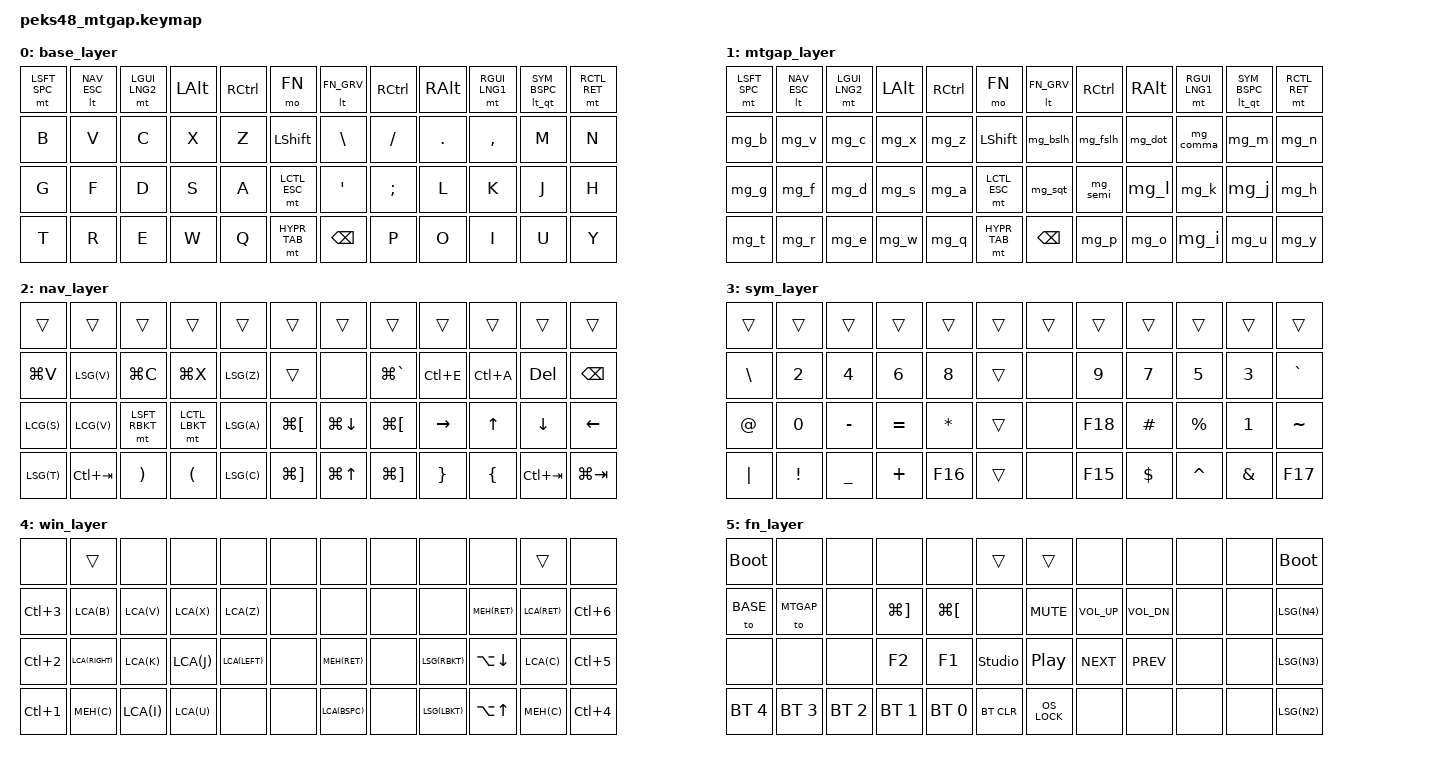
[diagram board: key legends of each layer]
// Includes {{{

#include <input/processors.dtsi>
#include <dt-bindings/zmk/input_transform.h>
#include <zephyr/dt-bindings/input/input-event-codes.h>
#include <behaviors.dtsi>
#include <dt-bindings/zmk/bt.h>
#include <dt-bindings/zmk/keys.h>
#include <dt-bindings/zmk/pointing.h>
#include <dt-bindings/zmk/behaviors.h>

// }}}

// Macros {{{

// Layers
#define BASE  0
#define MTGAP 1
#define NAV   2
#define SYM   3
#define WIN   4
#define FN    5

// Modifiers
#define LSG(key) LS(LG(key))
#define LCA(key) LC(LA(key))
#define LCG(key) LC(LG(key))
#define MEH(key) LS(LC(LA(key)))
#define HYPER    RC(RA(RG(RSHIFT)))

// Layer-Tap
#define NAV_ESC  NAV ESC
#define SYM_BSPC SYM BSPC
#define FN_GRV   FN  GRAVE

// Mod-Tap
#define HYPR_TAB  HYPER  TAB
#define LSFT_SPC  LSHIFT SPACE
#define RCTL_RET  RCTRL  RET
#define LCTL_ESC  LCTRL  ESC
#define LGUI_LNG2 LGUI   LANG2
#define RGUI_LNG1 RGUI   LANG1
#define RGUI_TAB  RGUI   TAB
#define LCTL_LBKT LCTRL  LBKT
#define LSFT_RBKT LSHIFT RBKT

// Otherwise
#define OS_LOCK LCG(Q)

// }}}

// Behavior Configuration {{{

&mt {
    tapping-term-ms = <150>;
};

&lt {
    flavor = "hold-preferred";
    tapping-term-ms = <150>;
};

// }}}

/ {

    // Behaviors {{{

    behaviors {

        mt_qt: mod_tap_with_quick_tap {
            compatible = "zmk,behavior-hold-tap";
            #binding-cells = <2>;
            flavor = "hold-preferred";
            tapping-term-ms = <150>;
            quick-tap-ms = <150>;
            bindings = <&kp>, <&kp>;
            display-name = "Mod-Tap";
        };

        lt_qt: layer_tap_with_quick_tap {
            compatible = "zmk,behavior-hold-tap";
            #binding-cells = <2>;
            flavor = "hold-preferred";
            tapping-term-ms = <150>;
            quick-tap-ms = <150>;
            bindings = <&mo>, <&kp>;
            display-name = "Layer-Tap";
        };

        // MTGAP {{{

        mg_a: mtgap_a {
            compatible = "zmk,behavior-mod-morph";
            #binding-cells = <0>;
            bindings = <&kp I>, <&kp A>;
            mods = <(MOD_LCTL|MOD_RCTL|MOD_LGUI|MOD_RGUI)>;
            keep-mods = <(MOD_LCTL|MOD_RCTL|MOD_LGUI|MOD_RGUI)>;
        };

        mg_b: mtgap_b {
            compatible = "zmk,behavior-mod-morph";
            #binding-cells = <0>;
            bindings = <&kp SEMI>, <&kp B>;
            mods = <(MOD_LCTL|MOD_RCTL|MOD_LGUI|MOD_RGUI)>;
            keep-mods = <(MOD_LCTL|MOD_RCTL|MOD_LGUI|MOD_RGUI)>;
        };

        mg_c: mtgap_c {
            compatible = "zmk,behavior-mod-morph";
            #binding-cells = <0>;
            bindings = <&kp SQT>, <&kp C>;
            mods = <(MOD_LCTL|MOD_RCTL|MOD_LGUI|MOD_RGUI)>;
            keep-mods = <(MOD_LCTL|MOD_RCTL|MOD_LGUI|MOD_RGUI)>;
        };

        mg_d: mtgap_d {
            compatible = "zmk,behavior-mod-morph";
            #binding-cells = <0>;
            bindings = <&kp E>, <&kp D>;
            mods = <(MOD_LCTL|MOD_RCTL|MOD_LGUI|MOD_RGUI)>;
            keep-mods = <(MOD_LCTL|MOD_RCTL|MOD_LGUI|MOD_RGUI)>;
        };

        mg_e: mtgap_e {
            compatible = "zmk,behavior-mod-morph";
            #binding-cells = <0>;
            bindings = <&kp O>, <&kp E>;
            mods = <(MOD_LCTL|MOD_RCTL|MOD_LGUI|MOD_RGUI)>;
            keep-mods = <(MOD_LCTL|MOD_RCTL|MOD_LGUI|MOD_RGUI)>;
        };

        mg_f: mtgap_f {
            compatible = "zmk,behavior-mod-morph";
            #binding-cells = <0>;
            bindings = <&kp A>, <&kp F>;
            mods = <(MOD_LCTL|MOD_RCTL|MOD_LGUI|MOD_RGUI)>;
            keep-mods = <(MOD_LCTL|MOD_RCTL|MOD_LGUI|MOD_RGUI)>;
        };

        mg_g: mtgap_g {
            compatible = "zmk,behavior-mod-morph";
            #binding-cells = <0>;
            bindings = <&kp COMMA>, <&kp G>;
            mods = <(MOD_LCTL|MOD_RCTL|MOD_LGUI|MOD_RGUI)>;
            keep-mods = <(MOD_LCTL|MOD_RCTL|MOD_LGUI|MOD_RGUI)>;
        };

        mg_h: mtgap_h {
            compatible = "zmk,behavior-mod-morph";
            #binding-cells = <0>;
            bindings = <&kp M>, <&kp H>;
            mods = <(MOD_LCTL|MOD_RCTL|MOD_LGUI|MOD_RGUI)>;
            keep-mods = <(MOD_LCTL|MOD_RCTL|MOD_LGUI|MOD_RGUI)>;
        };

        mg_i: mtgap_i {
            compatible = "zmk,behavior-mod-morph";
            #binding-cells = <0>;
            bindings = <&kp L>, <&kp I>;
            mods = <(MOD_LCTL|MOD_RCTL|MOD_LGUI|MOD_RGUI)>;
            keep-mods = <(MOD_LCTL|MOD_RCTL|MOD_LGUI|MOD_RGUI)>;
        };

        mg_j: mtgap_j {
            compatible = "zmk,behavior-mod-morph";
            #binding-cells = <0>;
            bindings = <&kp H>, <&kp J>;
            mods = <(MOD_LCTL|MOD_RCTL|MOD_LGUI|MOD_RGUI)>;
            keep-mods = <(MOD_LCTL|MOD_RCTL|MOD_LGUI|MOD_RGUI)>;
        };

        mg_k: mtgap_k {
            compatible = "zmk,behavior-mod-morph";
            #binding-cells = <0>;
            bindings = <&kp T>, <&kp K>;
            mods = <(MOD_LCTL|MOD_RCTL|MOD_LGUI|MOD_RGUI)>;
            keep-mods = <(MOD_LCTL|MOD_RCTL|MOD_LGUI|MOD_RGUI)>;
        };

        mg_l: mtgap_l {
            compatible = "zmk,behavior-mod-morph";
            #binding-cells = <0>;
            bindings = <&kp S>, <&kp L>;
            mods = <(MOD_LCTL|MOD_RCTL|MOD_LGUI|MOD_RGUI)>;
            keep-mods = <(MOD_LCTL|MOD_RCTL|MOD_LGUI|MOD_RGUI)>;
        };

        mg_m: mtgap_m {
            compatible = "zmk,behavior-mod-morph";
            #binding-cells = <0>;
            bindings = <&kp F>, <&kp M>;
            mods = <(MOD_LCTL|MOD_RCTL|MOD_LGUI|MOD_RGUI)>;
            keep-mods = <(MOD_LCTL|MOD_RCTL|MOD_LGUI|MOD_RGUI)>;
        };

        mg_n: mtgap_n {
            compatible = "zmk,behavior-mod-morph";
            #binding-cells = <0>;
            bindings = <&kp B>, <&kp N>;
            mods = <(MOD_LCTL|MOD_RCTL|MOD_LGUI|MOD_RGUI)>;
            keep-mods = <(MOD_LCTL|MOD_RCTL|MOD_LGUI|MOD_RGUI)>;
        };

        mg_o: mtgap_o {
            compatible = "zmk,behavior-mod-morph";
            #binding-cells = <0>;
            bindings = <&kp C>, <&kp O>;
            mods = <(MOD_LCTL|MOD_RCTL|MOD_LGUI|MOD_RGUI)>;
            keep-mods = <(MOD_LCTL|MOD_RCTL|MOD_LGUI|MOD_RGUI)>;
        };

        mg_p: mtgap_p {
            compatible = "zmk,behavior-mod-morph";
            #binding-cells = <0>;
            bindings = <&kp W>, <&kp P>;
            mods = <(MOD_LCTL|MOD_RCTL|MOD_LGUI|MOD_RGUI)>;
            keep-mods = <(MOD_LCTL|MOD_RCTL|MOD_LGUI|MOD_RGUI)>;
        };

        mg_q: mtgap_q {
            compatible = "zmk,behavior-mod-morph";
            #binding-cells = <0>;
            bindings = <&kp Y>, <&kp Q>;
            mods = <(MOD_LCTL|MOD_RCTL|MOD_LGUI|MOD_RGUI)>;
            keep-mods = <(MOD_LCTL|MOD_RCTL|MOD_LGUI|MOD_RGUI)>;
        };

        mg_r: mtgap_r {
            compatible = "zmk,behavior-mod-morph";
            #binding-cells = <0>;
            bindings = <&kp U>, <&kp R>;
            mods = <(MOD_LCTL|MOD_RCTL|MOD_LGUI|MOD_RGUI)>;
            keep-mods = <(MOD_LCTL|MOD_RCTL|MOD_LGUI|MOD_RGUI)>;
        };

        mg_s: mtgap_s {
            compatible = "zmk,behavior-mod-morph";
            #binding-cells = <0>;
            bindings = <&kp N>, <&kp S>;
            mods = <(MOD_LCTL|MOD_RCTL|MOD_LGUI|MOD_RGUI)>;
            keep-mods = <(MOD_LCTL|MOD_RCTL|MOD_LGUI|MOD_RGUI)>;
        };

        mg_t: mtgap_t {
            compatible = "zmk,behavior-mod-morph";
            #binding-cells = <0>;
            bindings = <&kp J>, <&kp T>;
            mods = <(MOD_LCTL|MOD_RCTL|MOD_LGUI|MOD_RGUI)>;
            keep-mods = <(MOD_LCTL|MOD_RCTL|MOD_LGUI|MOD_RGUI)>;
        };

        mg_u: mtgap_u {
            compatible = "zmk,behavior-mod-morph";
            #binding-cells = <0>;
            bindings = <&kp D>, <&kp U>;
            mods = <(MOD_LCTL|MOD_RCTL|MOD_LGUI|MOD_RGUI)>;
            keep-mods = <(MOD_LCTL|MOD_RCTL|MOD_LGUI|MOD_RGUI)>;
        };

        mg_v: mtgap_v {
            compatible = "zmk,behavior-mod-morph";
            #binding-cells = <0>;
            bindings = <&kp DOT>, <&kp V>;
            mods = <(MOD_LCTL|MOD_RCTL|MOD_LGUI|MOD_RGUI)>;
            keep-mods = <(MOD_LCTL|MOD_RCTL|MOD_LGUI|MOD_RGUI)>;
        };

        mg_w: mtgap_w {
            compatible = "zmk,behavior-mod-morph";
            #binding-cells = <0>;
            bindings = <&kp P>, <&kp W>;
            mods = <(MOD_LCTL|MOD_RCTL|MOD_LGUI|MOD_RGUI)>;
            keep-mods = <(MOD_LCTL|MOD_RCTL|MOD_LGUI|MOD_RGUI)>;
        };

        mg_x: mtgap_x {
            compatible = "zmk,behavior-mod-morph";
            #binding-cells = <0>;
            bindings = <&kp FSLH>, <&kp X>;
            mods = <(MOD_LCTL|MOD_RCTL|MOD_LGUI|MOD_RGUI)>;
            keep-mods = <(MOD_LCTL|MOD_RCTL|MOD_LGUI|MOD_RGUI)>;
        };

        mg_y: mtgap_y {
            compatible = "zmk,behavior-mod-morph";
            #binding-cells = <0>;
            bindings = <&kp K>, <&kp Y>;
            mods = <(MOD_LCTL|MOD_RCTL|MOD_LGUI|MOD_RGUI)>;
            keep-mods = <(MOD_LCTL|MOD_RCTL|MOD_LGUI|MOD_RGUI)>;
        };

        mg_z: mtgap_z {
            compatible = "zmk,behavior-mod-morph";
            #binding-cells = <0>;
            bindings = <&kp Q>, <&kp Z>;
            mods = <(MOD_LCTL|MOD_RCTL|MOD_LGUI|MOD_RGUI)>;
            keep-mods = <(MOD_LCTL|MOD_RCTL|MOD_LGUI|MOD_RGUI)>;
        };

        mg_comma: mtgap_comma {
            compatible = "zmk,behavior-mod-morph";
            #binding-cells = <0>;
            bindings = <&kp G>, <&kp COMMA>;
            mods = <(MOD_LCTL|MOD_RCTL|MOD_LGUI|MOD_RGUI)>;
            keep-mods = <(MOD_LCTL|MOD_RCTL|MOD_LGUI|MOD_RGUI)>;
        };

        mg_dot: mtgap_dot {
            compatible = "zmk,behavior-mod-morph";
            #binding-cells = <0>;
            bindings = <&kp V>, <&kp DOT>;
            mods = <(MOD_LCTL|MOD_RCTL|MOD_LGUI|MOD_RGUI)>;
            keep-mods = <(MOD_LCTL|MOD_RCTL|MOD_LGUI|MOD_RGUI)>;
        };

        mg_fslh: mtgap_fslh {
            compatible = "zmk,behavior-mod-morph";
            #binding-cells = <0>;
            bindings = <&kp X>, <&kp FSLH>;
            mods = <(MOD_LCTL|MOD_RCTL|MOD_LGUI|MOD_RGUI)>;
            keep-mods = <(MOD_LCTL|MOD_RCTL|MOD_LGUI|MOD_RGUI)>;
        };

        mg_semi: mtgap_semi {
            compatible = "zmk,behavior-mod-morph";
            #binding-cells = <0>;
            bindings = <&kp R>, <&kp SEMI>;
            mods = <(MOD_LCTL|MOD_RCTL|MOD_LGUI|MOD_RGUI)>;
            keep-mods = <(MOD_LCTL|MOD_RCTL|MOD_LGUI|MOD_RGUI)>;
        };

        mg_sqt: mtgap_sqt {
            compatible = "zmk,behavior-mod-morph";
            #binding-cells = <0>;
            bindings = <&kp Z>, <&kp SQT>;
            mods = <(MOD_LCTL|MOD_RCTL|MOD_LGUI|MOD_RGUI)>;
            keep-mods = <(MOD_LCTL|MOD_RCTL|MOD_LGUI|MOD_RGUI)>;
        };

        mg_bslh: mtgap_bslh {
            compatible = "zmk,behavior-mod-morph";
            #binding-cells = <0>;
            bindings = <&kp BSLH>, <&kp BSLH>;
            mods = <(MOD_LCTL|MOD_RCTL|MOD_LGUI|MOD_RGUI)>;
            keep-mods = <(MOD_LCTL|MOD_RCTL|MOD_LGUI|MOD_RGUI)>;
        };

        // }}}

    };

    // }}}

    // Conditional Layers {{{

    conditional_layers {
        compatible = "zmk,conditional-layers";
        tri_layer {
            if-layers = <NAV SYM>;
            then-layer = <WIN>;
        };
    };

    // }}}

    keymap {
        compatible = "zmk,keymap";

        base_layer {
            bindings = <
&mt LSFT_SPC  &lt NAV_ESC  &mt LGUI_LNG2  &kp LALT  &kp RCTRL  &mo FN            &lt FN_GRV  &kp RCTRL  &kp RALT  &mt RGUI_LNG1  &lt_qt SYM_BSPC  &mt RCTL_RET
&kp B         &kp V        &kp C          &kp X     &kp Z      &kp LSHIFT        &kp BSLH    &kp FSLH   &kp DOT   &kp COMMA      &kp M            &kp N
&kp G         &kp F        &kp D          &kp S     &kp A      &mt LCTL_ESC      &kp SQT     &kp SEMI   &kp L     &kp K          &kp J            &kp H
&kp T         &kp R        &kp E          &kp W     &kp Q      &mt HYPR_TAB      &kp BSPC    &kp P      &kp O     &kp I          &kp U            &kp Y
            >;
        };

//         base_layer {
//             bindings = <
// &mt HYPR_TAB  &kp Q      &kp W     &kp E          &kp R        &kp T             &kp Y         &kp U            &kp I          &kp O     &kp P      &kp BSPC
// &mt LCTL_ESC  &kp A      &kp S     &kp D          &kp F        &kp G             &kp H         &kp J            &kp K          &kp L     &kp SEMI   &kp SQT
// &kp LSHIFT    &kp Z      &kp X     &kp C          &kp V        &kp B             &kp N         &kp M            &kp COMMA      &kp DOT   &kp FSLH   &kp BSLH
// &mo FN        &kp RCTRL  &kp LALT  &mt LGUI_LNG2  &lt NAV_ESC  &mt LSFT_SPC      &mt RCTL_RET  &lt_qt SYM_BSPC  &mt RGUI_LNG1  &kp RALT  &kp RCTRL  &lt FN_GRV
//             >;
//         };

        mtgap_layer {
            bindings = <
&mt LSFT_SPC  &lt NAV_ESC  &mt LGUI_LNG2  &kp LALT  &kp RCTRL  &mo FN            &lt FN_GRV  &kp RCTRL  &kp RALT  &mt RGUI_LNG1  &lt_qt SYM_BSPC  &mt RCTL_RET
&mg_b         &mg_v        &mg_c          &mg_x     &mg_z      &kp LSHIFT        &mg_bslh    &mg_fslh   &mg_dot   &mg_comma      &mg_m            &mg_n
&mg_g         &mg_f        &mg_d          &mg_s     &mg_a      &mt LCTL_ESC      &mg_sqt     &mg_semi   &mg_l     &mg_k          &mg_j            &mg_h
&mg_t         &mg_r        &mg_e          &mg_w     &mg_q      &mt HYPR_TAB      &kp BSPC    &mg_p      &mg_o     &mg_i          &mg_u            &mg_y
            >;
        };

//         mtgap_layer {
//             bindings = <
// &mt HYPR_TAB  &mg_q      &mg_w     &mg_e          &mg_r        &mg_t             &mg_y         &mg_u            &mg_i          &mg_o     &mg_p      &kp BSPC
// &mt LCTL_ESC  &mg_a      &mg_s     &mg_d          &mg_f        &mg_g             &mg_h         &mg_j            &mg_k          &mg_l     &mg_semi   &mg_sqt
// &kp LSHIFT    &mg_z      &mg_x     &mg_c          &mg_v        &mg_b             &mg_n         &mg_m            &mg_comma      &mg_dot   &mg_fslh   &mg_bslh
// &mo FN        &kp RCTRL  &kp LALT  &mt LGUI_LNG2  &lt NAV_ESC  &mt LSFT_SPC      &mt RCTL_RET  &lt_qt SYM_BSPC  &mt RGUI_LNG1  &kp RALT  &kp RCTRL  &lt FN_GRV
//             >;
//         };

        nav_layer {
            bindings = <
&trans      &trans       &trans         &trans         &trans      &trans            &trans        &trans         &trans     &trans     &trans       &trans
&kp LG(V)   &kp LSG(V)   &kp LG(C)      &kp LG(X)      &kp LSG(Z)  &trans            &none         &kp LG(GRAVE)  &kp LC(E)  &kp LC(A)  &kp DEL      &kp BSPC
&kp LCG(S)  &kp LCG(V)   &mt LSFT_RBKT  &mt LCTL_LBKT  &kp LSG(A)  &kp LG(LBKT)      &kp LG(DOWN)  &kp LG(LBKT)   &kp RIGHT  &kp UP     &kp DOWN     &kp LEFT
&kp LSG(T)  &kp LC(TAB)  &kp RPAR       &kp LPAR       &kp LSG(C)  &kp LG(RBKT)      &kp LG(UP)    &kp LG(RBKT)   &kp RBRC   &kp LBRC   &kp LC(TAB)  &kp LG(TAB)
            >;
        };

//         nav_layer {
//             bindings = <
// &kp LG(RBKT)  &kp LSG(C)  &kp LPAR       &kp RPAR       &kp LC(TAB)  &kp LSG(T)      &kp LG(TAB)  &kp LC(TAB)  &kp LBRC   &kp RBRC   &kp LG(RBKT)   &kp LG(UP)
// &kp LG(LBKT)  &kp LSG(A)  &mt LCTL_LBKT  &mt LSFT_RBKT  &kp LCG(V)   &kp LCG(S)      &kp LEFT     &kp DOWN     &kp UP     &kp RIGHT  &kp LG(LBKT)   &kp LG(DOWN)
// &trans        &kp LSG(Z)  &kp LG(X)      &kp LG(C)      &kp LSG(V)   &kp LG(V)       &kp BSPC     &kp DEL      &kp LC(A)  &kp LC(E)  &kp LG(GRAVE)  &none
// &trans        &trans      &trans         &trans         &trans       &trans          &trans       &trans       &trans     &trans     &trans         &trans
//             >;
//         };

        sym_layer {
            bindings = <
&trans    &trans    &trans     &trans     &trans    &trans      &trans  &trans     &trans    &trans     &trans    &trans
&kp BSLH  &kp N2    &kp N4     &kp N6     &kp N8    &trans      &none   &kp N9     &kp N7    &kp N5     &kp N3    &kp GRAVE
&kp AT    &kp N0    &kp MINUS  &kp EQUAL  &kp STAR  &trans      &none   &kp F18    &kp HASH  &kp PRCNT  &kp N1    &kp TILDE
&kp PIPE  &kp EXCL  &kp UNDER  &kp PLUS   &kp F16   &trans      &none   &kp F15    &kp DLLR  &kp CARET  &kp AMPS  &kp F17
            >;
        };

//         sym_layer {
//             bindings = <
// &trans  &kp F16   &kp PLUS   &kp UNDER  &kp EXCL  &kp PIPE      &kp F17    &kp AMPS  &kp CARET  &kp DLLR  &kp F15    &none
// &trans  &kp STAR  &kp EQUAL  &kp MINUS  &kp N0    &kp AT        &kp TILDE  &kp N1    &kp PRCNT  &kp HASH  &kp F18    &none
// &trans  &kp N8    &kp N6     &kp N4     &kp N2    &kp BSLH      &kp GRAVE  &kp N3    &kp N5     &kp N7    &kp N9     &none
// &trans  &trans    &trans     &trans     &trans    &trans        &trans     &trans    &trans     &trans    &trans     &trans
//             >;
//         };
//
// F15, F16, F17, F18 は Karabiner-Elements で記号に変換する
// 英語入力／日本語入力のどちらでも半角記号を入力
// - F15 -> ,
// - F16 -> .
// - F17 -> /
// - F18 -> :

        win_layer {
            bindings = <
&none       &trans          &none       &none       &none          &none      &none          &none  &none          &none         &trans        &none
&kp LC(N3)  &kp LCA(B)      &kp LCA(V)  &kp LCA(X)  &kp LCA(Z)     &none      &none          &none  &none          &kp MEH(RET)  &kp LCA(RET)  &kp LC(N6)
&kp LC(N2)  &kp LCA(RIGHT)  &kp LCA(K)  &kp LCA(J)  &kp LCA(LEFT)  &none      &kp MEH(RET)   &none  &kp LSG(RBKT)  &kp LA(DOWN)  &kp LCA(C)    &kp LC(N5)
&kp LC(N1)  &kp MEH(C)      &kp LCA(I)  &kp LCA(U)  &none          &none      &kp LCA(BSPC)  &none  &kp LSG(LBKT)  &kp LA(UP)    &kp MEH(C)    &kp LC(N4)
            >;
        };

//         win_layer {
//             bindings = <
// &none  &none          &kp LCA(U)  &kp LCA(I)  &kp MEH(C)      &kp LC(N1)      &kp LC(N4)  &kp MEH(C)    &kp LA(UP)    &kp LSG(LBKT)  &none  &kp LCA(BSPC)
// &none  &kp LCA(LEFT)  &kp LCA(J)  &kp LCA(K)  &kp LCA(RIGHT)  &kp LC(N2)      &kp LC(N5)  &kp LCA(C)    &kp LA(DOWN)  &kp LSG(RBKT)  &none  &kp MEH(RET)
// &none  &kp LCA(Z)     &kp LCA(X)  &kp LCA(V)  &kp LCA(B)      &kp LC(N3)      &kp LC(N6)  &kp LCA(RET)  &kp MEH(RET)  &none          &none  &none
// &none  &none          &none       &none       &trans          &none           &none       &trans        &none         &none          &none  &none
//             >;
//         };

        fn_layer {
            bindings = <
&bootloader   &none         &none         &none         &none         &trans              &trans       &none         &none         &none  &none  &bootloader
&to BASE      &to MTGAP     &none         &kp LG(RBKT)  &kp LG(LBKT)  &none               &kp C_MUTE   &kp C_VOL_UP  &kp C_VOL_DN  &none  &none  &kp LSG(N4)
&none         &none         &none         &kp F2        &kp F1        &studio_unlock      &kp C_PP     &kp C_NEXT    &kp C_PREV    &none  &none  &kp LSG(N3)
&bt BT_SEL 4  &bt BT_SEL 3  &bt BT_SEL 2  &bt BT_SEL 1  &bt BT_SEL 0  &bt BT_CLR          &kp OS_LOCK  &none         &none         &none  &none  &kp LSG(N2)
            >;
        };

//         fn_layer {
//             bindings = <
// &bt BT_CLR      &bt BT_SEL 0  &bt BT_SEL 1  &bt BT_SEL 2  &bt BT_SEL 3  &bt BT_SEL 4      &kp LSG(N2)  &none  &none  &none         &none         &kp OS_LOCK
// &studio_unlock  &kp F1        &kp F2        &none         &none         &none             &kp LSG(N3)  &none  &none  &kp C_PREV    &kp C_NEXT    &kp C_PP
// &none           &kp LG(LBKT)  &kp LG(RBKT)  &none         &to MTGAP     &to BASE          &kp LSG(N4)  &none  &none  &kp C_VOL_DN  &kp C_VOL_UP  &kp C_MUTE
// &trans          &none         &none         &none         &none         &bootloader       &bootloader  &none  &none  &none         &none         &trans
//             >;
//         };

    };
};
